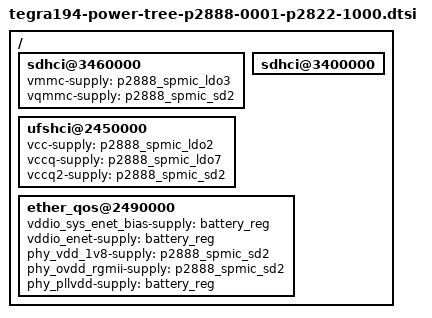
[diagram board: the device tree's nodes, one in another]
/*
 * Copyright (c) 2017, NVIDIA CORPORATION.  All rights reserved.
 *
 * This program is free software; you can redistribute it and/or modify
 * it under the terms of the GNU General Public License as published by
 * the Free Software Foundation; either version 2 of the License, or
 * (at your option) any later version.
 *
 * This program is distributed in the hope that it will be useful, but WITHOUT
 * ANY WARRANTY; without even the implied warranty of MERCHANTABILITY or
 * FITNESS FOR A PARTICULAR PURPOSE.  See the GNU General Public License for
 * more details.
 */

#include "tegra194-spmic-p2888-0001.dtsi"
#include "tegra194-fixed-regulator-p2888-0001.dtsi"
#include "tegra194-fixed-regulator-p2822-1000.dtsi"
#include "dt-bindings/gpio/tegra194-gpio.h"

/ {
	sdhci@3460000 {
		vmmc-supply = <&p2888_spmic_ldo3>;
		vqmmc-supply = <&p2888_spmic_sd2>;
	};

	sdhci@3400000 {
		/* vmmc-supply = <&tegra_main_gpio TEGRA_MAIN_GPIO(A, 0) 1>; */
	};

	ufshci@2450000 {
		vcc-supply = <&p2888_spmic_ldo2>;
		vccq-supply = <&p2888_spmic_ldo7>;
		vccq2-supply = <&p2888_spmic_sd2>;
	};

	ether_qos@2490000 {
		vddio_sys_enet_bias-supply = <&battery_reg>;
		vddio_enet-supply = <&battery_reg>;
		phy_vdd_1v8-supply = <&p2888_spmic_sd2>;
		phy_ovdd_rgmii-supply = <&p2888_spmic_sd2>;
		phy_pllvdd-supply = <&battery_reg>;
	};

};
